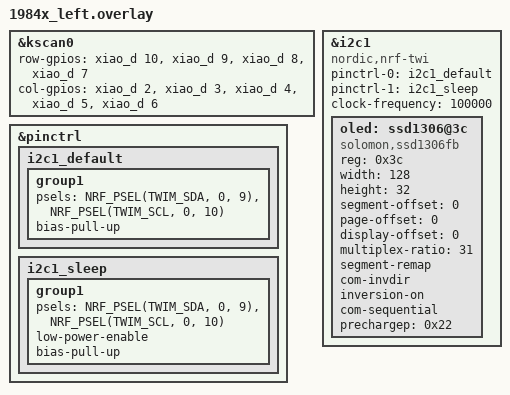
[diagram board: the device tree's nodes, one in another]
#include "1984x.dtsi"

&kscan0 {
    row-gpios
        = <&xiao_d 10 (GPIO_ACTIVE_HIGH | GPIO_PULL_DOWN)>
        , <&xiao_d 9 (GPIO_ACTIVE_HIGH | GPIO_PULL_DOWN)>
        , <&xiao_d 8 (GPIO_ACTIVE_HIGH | GPIO_PULL_DOWN)>
        , <&xiao_d 7 (GPIO_ACTIVE_HIGH | GPIO_PULL_DOWN)>
        ;

    col-gpios
        = <&xiao_d 2 GPIO_ACTIVE_HIGH>
        , <&xiao_d 3 GPIO_ACTIVE_HIGH>
        , <&xiao_d 4 GPIO_ACTIVE_HIGH>
        , <&xiao_d 5 GPIO_ACTIVE_HIGH>
        , <&xiao_d 6 GPIO_ACTIVE_HIGH>
        ;
};


&pinctrl {
    i2c1_default: i2c1_default {
		group1 {
			psels = <NRF_PSEL(TWIM_SDA, 0, 9)>,
					<NRF_PSEL(TWIM_SCL, 0, 10)>;
            bias-pull-up;
		};
	};

	i2c1_sleep: i2c1_sleep {
		group1 {
			psels = <NRF_PSEL(TWIM_SDA, 0, 9)>,
					<NRF_PSEL(TWIM_SCL, 0, 10)>;
			low-power-enable;
            bias-pull-up;
		};
	};
};


&i2c1 {
	status = "okay";

	compatible = "nordic,nrf-twi";
    pinctrl-0 = <&i2c1_default>;
	pinctrl-1 = <&i2c1_sleep>;
	pinctrl-names = "default", "sleep";
    clock-frequency = <100000>;

    oled: ssd1306@3c {
        compatible = "solomon,ssd1306fb";
        reg = <0x3c>;
        width = <128>;
        height = <32>;
        segment-offset = <0>;
        page-offset = <0>;
        display-offset = <0>;
        multiplex-ratio = <31>;
        segment-remap;
        com-invdir;
        inversion-on;
        com-sequential;
        prechargep = <0x22>;
        status = "okay";
    };
};
/*

/ {
    chosen {
        zephyr,display = &oled;
    };
};*/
